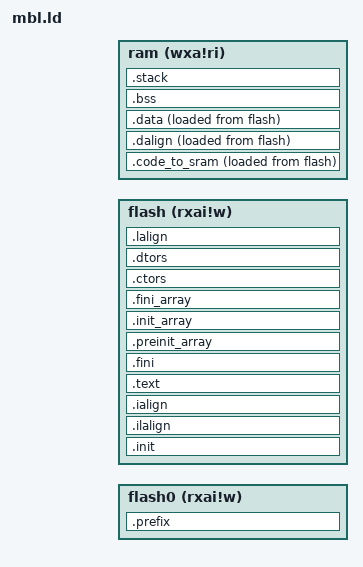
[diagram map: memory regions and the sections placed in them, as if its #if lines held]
/*!
    \file    mbl.ld
    \brief   Load file for main bootloader for GD32VW55x SDK.

    \version 2023-07-20, V1.0.0, firmware for GD32VW55x
*/

/*
    Copyright (c) 2023, GigaDevice Semiconductor Inc.

    Redistribution and use in source and binary forms, with or without modification,
are permitted provided that the following conditions are met:

    1. Redistributions of source code must retain the above copyright notice, this
       list of conditions and the following disclaimer.
    2. Redistributions in binary form must reproduce the above copyright notice,
       this list of conditions and the following disclaimer in the documentation
       and/or other materials provided with the distribution.
    3. Neither the name of the copyright holder nor the names of its contributors
       may be used to endorse or promote products derived from this software without
       specific prior written permission.

    THIS SOFTWARE IS PROVIDED BY THE COPYRIGHT HOLDERS AND CONTRIBUTORS "AS IS"
AND ANY EXPRESS OR IMPLIED WARRANTIES, INCLUDING, BUT NOT LIMITED TO, THE IMPLIED
WARRANTIES OF MERCHANTABILITY AND FITNESS FOR A PARTICULAR PURPOSE ARE DISCLAIMED.
IN NO EVENT SHALL THE COPYRIGHT HOLDER OR CONTRIBUTORS BE LIABLE FOR ANY DIRECT,
INDIRECT, INCIDENTAL, SPECIAL, EXEMPLARY, OR CONSEQUENTIAL DAMAGES (INCLUDING, BUT
NOT LIMITED TO, PROCUREMENT OF SUBSTITUTE GOODS OR SERVICES; LOSS OF USE, DATA, OR
PROFITS; OR BUSINESS INTERRUPTION) HOWEVER CAUSED AND ON ANY THEORY OF LIABILITY,
WHETHER IN CONTRACT, STRICT LIABILITY, OR TORT (INCLUDING NEGLIGENCE OR OTHERWISE)
ARISING IN ANY WAY OUT OF THE USE OF THIS SOFTWARE, EVEN IF ADVISED OF THE POSSIBILITY
OF SUCH DAMAGE.
*/

#include "mbl_region.h"

OUTPUT_ARCH( "riscv" )

ENTRY( _start )

MEMORY
{
    /* Run in FLASH */
#if IMG_OVERHEAD_LEN == 0
    flash0 (rxai!w) : ORIGIN = RE_FLASH_BASE + RE_SYS_SET_OFFSET, LENGTH = MBL_COMPAT_PREFIX
#endif
    flash (rxai!w) : ORIGIN = MBL_CODE_START, LENGTH = MBL_CODE_SIZE
    ram   (wxa!ri) : ORIGIN = MBL_DATA_START, LENGTH = MBL_DATA_SIZE
}


SECTIONS
{
  __stack_size = MBL_MSP_STACK_SIZE;

#if IMG_OVERHEAD_LEN == 0
  .prefix           :
  {
    KEEP (*mbl.o* (.data.compat_prefix))
  } >flash0 AT>flash0
#endif

  .init           :
  {
    KEEP (*(SORT_NONE(.init)))
  } >flash AT>flash

  .ilalign         :
  {
    . = ALIGN(4);
    PROVIDE( _ilm_lma = . );
  } >flash AT>flash

  .ialign         :
  {
    PROVIDE( _ilm = . );
  } >flash AT>flash

  _sicode = LOADADDR(.code_to_sram);
  .code_to_sram :
  {
    . = ALIGN(4);
    _scode = .;
    _ecode = .;
  } >ram AT>flash

  .text           :
  {
    *(.rodata .rodata.*)
    *(.text.unlikely .text.unlikely.*)
    *(.text.startup .text.startup.*)
    *(.text .text.*)
    *(.gnu.linkonce.t.*)
    *(.srodata .srodata.*)
  } >flash AT>flash

  .fini           :
  {
    KEEP (*(SORT_NONE(.fini)))
  } >flash AT>flash

  . = ALIGN(4);

  PROVIDE (__etext = .);
  PROVIDE (_etext = .);/*0x80022c8*/
  PROVIDE (etext = .);/*0x80022c8*/
  PROVIDE( _eilm = . );

  .preinit_array  :
  {
    PROVIDE_HIDDEN (__preinit_array_start = .);
    KEEP (*(.preinit_array))
    PROVIDE_HIDDEN (__preinit_array_end = .);
  } >flash AT>flash

  .init_array     :
  {
    PROVIDE_HIDDEN (__init_array_start = .);
    KEEP (*(SORT_BY_INIT_PRIORITY(.init_array.*) SORT_BY_INIT_PRIORITY(.ctors.*)))
    KEEP (*(.init_array EXCLUDE_FILE (*crtbegin.o *crtbegin?.o *crtend.o *crtend?.o ) .ctors))
    PROVIDE_HIDDEN (__init_array_end = .);
  } >flash AT>flash

  .fini_array     :
  {
    PROVIDE_HIDDEN (__fini_array_start = .);
    KEEP (*(SORT_BY_INIT_PRIORITY(.fini_array.*) SORT_BY_INIT_PRIORITY(.dtors.*)))
    KEEP (*(.fini_array EXCLUDE_FILE (*crtbegin.o *crtbegin?.o *crtend.o *crtend?.o ) .dtors))
    PROVIDE_HIDDEN (__fini_array_end = .);
  } >flash AT>flash

  .ctors          :
  {
    /* gcc uses crtbegin.o to find the start of
       the constructors, so we make sure it is
       first.  Because this is a wildcard, it
       doesn't matter if the user does not
       actually link against crtbegin.o; the
       linker won't look for a file to match a
       wildcard.  The wildcard also means that it
       doesn't matter which directory crtbegin.o
       is in.  */
    KEEP (*crtbegin.o(.ctors))
    KEEP (*crtbegin?.o(.ctors))
    /* We don't want to include the .ctor section from
       the crtend.o file until after the sorted ctors.
       The .ctor section from the crtend file contains the
       end of ctors marker and it must be last */
    KEEP (*(EXCLUDE_FILE (*crtend.o *crtend?.o ) .ctors))
    KEEP (*(SORT(.ctors.*)))
    KEEP (*(.ctors))
  } >flash AT>flash

  .dtors          :
  {
    KEEP (*crtbegin.o(.dtors))
    KEEP (*crtbegin?.o(.dtors))
    KEEP (*(EXCLUDE_FILE (*crtend.o *crtend?.o ) .dtors))
    KEEP (*(SORT(.dtors.*)))
    KEEP (*(.dtors))
  } >flash AT>flash

    . = ALIGN(4);
    PROVIDE( _eilm = . );

  .lalign         :
  {
    . = ALIGN(4);
    PROVIDE( _data_lma = . );
  } >flash AT>flash

  .dalign         :
  {
    . = ALIGN(4);
    PROVIDE( _data = . );
  } >ram AT>flash


  .data          :
  {
    *(.rdata)

    *(.gnu.linkonce.r.*)
    *(.data .data.*)
    *(.gnu.linkonce.d.*)
    . = ALIGN(8);
    PROVIDE( __global_pointer$ = . + 0x800);
    *(.sdata .sdata.*)
    *(.gnu.linkonce.s.*)
    . = ALIGN(8);
  } >ram AT>flash

  . = ALIGN(4);
  PROVIDE( _edata = . );
  PROVIDE( edata = . );

  PROVIDE( _fbss = . ); /*0X200052A0  0X200002A0*/
  PROVIDE( __bss_start = . );
  .bss            :
  {
    *(.sbss*)
    *(.gnu.linkonce.sb.*)
    *(.bss .bss.*)
    *(.gnu.linkonce.b.*)
    *(COMMON)
    . = ALIGN(4);
  } >ram AT>ram

  . = ALIGN(8);
  PROVIDE( _end = . ); /*0X2000,0340*/
  PROVIDE( end = . );

  .stack ORIGIN(ram) + LENGTH(ram) - __stack_size :
  {
    PROVIDE( _heap_end = . );
    . = __stack_size;
    PROVIDE( _sp = . );
  } >ram AT>ram
}
